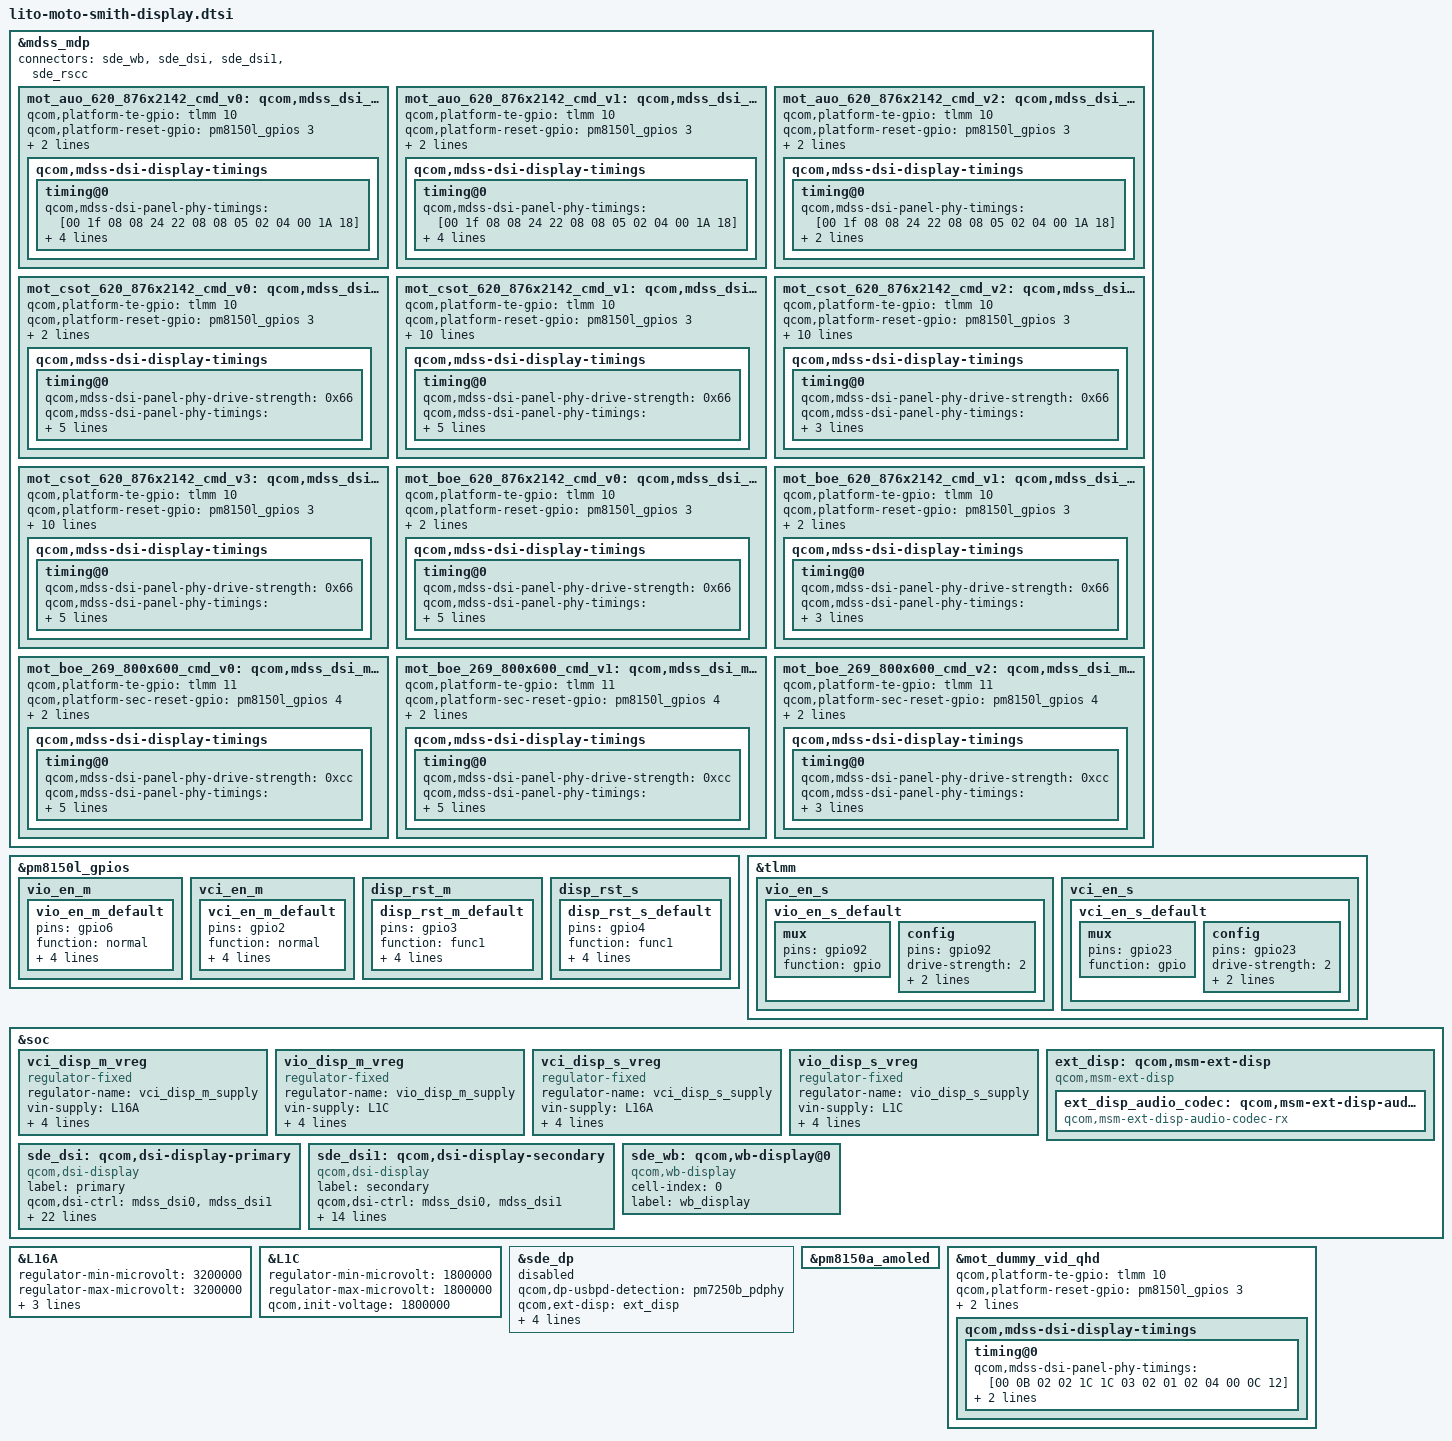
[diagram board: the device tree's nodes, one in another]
/* Copyright (c) 2019, The Linux Foundation. All rights reserved.
 *
 * This program is free software; you can redistribute it and/or modify
 * it under the terms of the GNU General Public License version 2 and
 * only version 2 as published by the Free Software Foundation.
 *
 * This program is distributed in the hope that it will be useful,
 * but WITHOUT ANY WARRANTY; without even the implied warranty of
 * MERCHANTABILITY or FITNESS FOR A PARTICULAR PURPOSE.  See the
 * GNU General Public License for more details.
 */
#include <dt-bindings/clock/mdss-7nm-pll-clk.h>
#include "dsi-panel-mot-dummy-qhd-video.dtsi"

&mdss_mdp {
	/* Primary Display: AUO */
	mot_auo_620_876x2142_cmd_v0: qcom,mdss_dsi_mot_auo_620_876x2142_cmd_v0 {
		#include "dsi-panel-mot-auo-620-876x2142-cmd-common.dtsi"
	};

	mot_auo_620_876x2142_cmd_v1: qcom,mdss_dsi_mot_auo_620_876x2142_cmd_v1 {
		#include "dsi-panel-mot-auo-620-876x2142-cmd-common.dtsi"
	};

	mot_auo_620_876x2142_cmd_v2: qcom,mdss_dsi_mot_auo_620_876x2142_cmd_v2 {
		#include "dsi-panel-mot-auo-620-876x2142-cmd-common.dtsi"
	};

        /* Primary Display:  CSOT */
        mot_csot_620_876x2142_cmd_v0: qcom,mdss_dsi_mot_csot_620_876x2142_cmd_v0 {
		#include "dsi-panel-mot-csot-620-876x2142-cmd-common.dtsi"
	};

	mot_csot_620_876x2142_cmd_v1: qcom,mdss_dsi_mot_csot_620_876x2142_cmd_v1 {
		#include "dsi-panel-mot-csot-620-876x2142-cmd-common.dtsi"
	};

	mot_csot_620_876x2142_cmd_v2: qcom,mdss_dsi_mot_csot_620_876x2142_cmd_v2 {
		#include "dsi-panel-mot-csot-620-876x2142-cmd-common.dtsi"
	};

	mot_csot_620_876x2142_cmd_v3: qcom,mdss_dsi_mot_csot_620_876x2142_cmd_v3 {
		#include "dsi-panel-mot-csot-620-876x2142-cmd-common.dtsi"
	};

	/* Primary Display:  BOE */
	mot_boe_620_876x2142_cmd_v0: qcom,mdss_dsi_mot_boe_620_876x2142_cmd_v0 {
		#include "dsi-panel-mot-boe-620-876x2142-cmd-common.dtsi"
	};

	/* Primary Display:  BOE */
	mot_boe_620_876x2142_cmd_v1: qcom,mdss_dsi_mot_boe_620_876x2142_cmd_v1 {
		#include "dsi-panel-mot-boe-620-876x2142-cmd-common.dtsi"
	};

	/* Secondary Display: BOE */
	mot_boe_269_800x600_cmd_v0: qcom,mdss_dsi_mot_boe_269_800x600_cmd_v0 {
		#include "dsi-panel-mot-boe-269-800x600-cmd-common.dtsi"
	};

	mot_boe_269_800x600_cmd_v1: qcom,mdss_dsi_mot_boe_269_800x600_cmd_v1 {
		#include "dsi-panel-mot-boe-269-800x600-cmd-common.dtsi"
	};

	mot_boe_269_800x600_cmd_v2: qcom,mdss_dsi_mot_boe_269_800x600_cmd_v2 {
		#include "dsi-panel-mot-boe-269-800x600-cmd-common.dtsi"
	};
};

&pm8150l_gpios {
        vio_en_m {
                vio_en_m_default: vio_en_m_default {
                        pins = "gpio6";
                        function = "normal";
                        qcom,drive-strength = <2>;
                        power-source = <0>;
                        bias-disable;
                        output-high;
                };
        };

	vci_en_m {
		vci_en_m_default: vci_en_m_default {
			pins = "gpio2";
			function = "normal";
			qcom,drive-strength = <2>;
			power-source = <0>;
			bias-disable;
			output-high;
		};
	};

        disp_rst_m {
                disp_rst_m_default: disp_rst_m_default {
                        pins = "gpio3";
                        function = "func1";
                        qcom,drive-strength = <2>;
                        power-source = <0>;
                        bias-disable;
                        output-low;
                };
	};

	disp_rst_s {
		disp_rst_s_default: disp_rst_s_default {
			pins = "gpio4";
			function = "func1";
			qcom,drive-strength = <2>;
			power-source = <0>;
			bias-disable;
			output-low;
		};
	};
};

&tlmm {
	vio_en_s {
		vio_en_s_default: vio_en_s_default {
			mux {
				pins = "gpio92";
				function = "gpio";
			};

			config {
				pins = "gpio92";
				drive-strength = <2>;   /* 2 mA */
				bias-no-pull;
				output-high;
			};
		};
	};

	vci_en_s {
		vci_en_s_default: vci_en_s_default {
			mux {
				pins = "gpio23";
				function = "gpio";
			};

			config {
				pins = "gpio23";
				drive-strength = <2>;   /* 2 mA */
				bias-no-pull;
				output-high;
			};
		};
	};
};

&soc {
	vci_disp_m_vreg: vci_disp_m_vreg {
		compatible = "regulator-fixed";
		regulator-name = "vci_disp_m_supply";
		vin-supply = <&L16A>;
		enable-active-high;
		regulator-boot-on;

		gpio = <&pm8150l_gpios 02 GPIO_ACTIVE_HIGH>;
		pinctrl-names = "default";
		pinctrl-0 = <&vci_en_m_default>;
	};

	vio_disp_m_vreg: vio_disp_m_vreg {
		compatible = "regulator-fixed";
		regulator-name = "vio_disp_m_supply";
		vin-supply = <&L1C>;
		enable-active-high;
		regulator-boot-on;

		gpio = <&pm8150l_gpios 6 GPIO_ACTIVE_HIGH>;
		pinctrl-names = "default";
		pinctrl-0 = <&vio_en_m_default>;
	};

	vci_disp_s_vreg: vci_disp_s_vreg {
		compatible = "regulator-fixed";
		regulator-name = "vci_disp_s_supply";
		vin-supply = <&L16A>;
		enable-active-high;
		regulator-boot-on;

		gpio = <&tlmm 23 GPIO_ACTIVE_HIGH>;
		pinctrl-names = "default";
		pinctrl-0 = <&vci_en_s_default>;
	};


	vio_disp_s_vreg: vio_disp_s_vreg {
		compatible = "regulator-fixed";
		regulator-name = "vio_disp_s_supply";
		vin-supply = <&L1C>;
		enable-active-high;
		regulator-boot-on;

		gpio = <&tlmm 92 GPIO_ACTIVE_HIGH>;
		pinctrl-names = "default";
		pinctrl-0 = <&vio_en_s_default>;
	};

	ext_disp: qcom,msm-ext-disp {
		compatible = "qcom,msm-ext-disp";

		ext_disp_audio_codec: qcom,msm-ext-disp-audio-codec-rx {
			compatible = "qcom,msm-ext-disp-audio-codec-rx";
		};
	};

	sde_dsi: qcom,dsi-display-primary {
		compatible = "qcom,dsi-display";
		label = "primary";

		qcom,dsi-ctrl = <&mdss_dsi0 &mdss_dsi1>;
		qcom,dsi-phy = <&mdss_dsi_phy0 &mdss_dsi_phy1>;

		clocks = <&mdss_dsi0_pll BYTECLK_MUX_0_CLK>,
			<&mdss_dsi0_pll PCLK_MUX_0_CLK>,
			<&mdss_dsi0_pll BYTECLK_SRC_0_CLK>,
			<&mdss_dsi0_pll PCLK_SRC_0_CLK>,
			<&mdss_dsi0_pll SHADOW_BYTECLK_SRC_0_CLK>,
			<&mdss_dsi0_pll SHADOW_PCLK_SRC_0_CLK>,
			<&mdss_dsi1_pll BYTECLK_MUX_1_CLK>,
			<&mdss_dsi1_pll PCLK_MUX_1_CLK>,
			<&mdss_dsi1_pll BYTECLK_SRC_1_CLK>,
			<&mdss_dsi1_pll PCLK_SRC_1_CLK>,
			<&mdss_dsi1_pll SHADOW_BYTECLK_SRC_1_CLK>,
			<&mdss_dsi1_pll SHADOW_PCLK_SRC_1_CLK>;
		clock-names = "mux_byte_clk0", "mux_pixel_clk0",
				"src_byte_clk0", "src_pixel_clk0",
				"shadow_byte_clk0", "shadow_pixel_clk0",
				"mux_byte_clk1", "mux_pixel_clk1",
				"src_byte_clk1", "src_pixel_clk1",
				"shadow_byte_clk1", "shadow_pixel_clk1";

		pinctrl-names = "panel_active", "panel_suspend";
		pinctrl-0 = <&sde_te_active &disp_rst_m_default>;
		pinctrl-1 = <&sde_te_suspend>;

		qcom,platform-te-gpio = <&tlmm 10 0>;
		qcom,panel-te-source = <0>;
		vci_disp-supply = <&vci_disp_m_vreg>;
		vio_disp-supply = <&vio_disp_m_vreg>;

		qcom,mdp = <&mdss_mdp>;
		qcom,dsi-default-panel = <&mot_boe_620_876x2142_cmd_v0>;
	};


	sde_dsi1: qcom,dsi-display-secondary {
		compatible = "qcom,dsi-display";
		label = "secondary";

		qcom,dsi-ctrl = <&mdss_dsi0 &mdss_dsi1>;
		qcom,dsi-phy = <&mdss_dsi_phy0 &mdss_dsi_phy1>;

		clocks = <&mdss_dsi0_pll BYTECLK_MUX_0_CLK>,
			<&mdss_dsi0_pll PCLK_MUX_0_CLK>,
			<&mdss_dsi1_pll BYTECLK_MUX_1_CLK>,
			<&mdss_dsi1_pll PCLK_MUX_1_CLK>;
		clock-names = "mux_byte_clk0", "mux_pixel_clk0",
				"mux_byte_clk1", "mux_pixel_clk1";

		pinctrl-names = "panel_active", "panel_suspend";
		pinctrl-0 = <&sde_te1_active &disp_rst_s_default>;
		pinctrl-1 = <&sde_te1_suspend>;

		qcom,platform-te-gpio = <&tlmm 11 0>;
		qcom,panel-te-source = <1>;
		vio_disp-supply = <&vio_disp_s_vreg>;
		vci_disp-supply = <&vci_disp_s_vreg>;

		qcom,mdp = <&mdss_mdp>;
                qcom,dsi-default-panel = <&mot_boe_269_800x600_cmd_v1>;
	};

	sde_wb: qcom,wb-display@0 {
		compatible = "qcom,wb-display";
		cell-index = <0>;
		label = "wb_display";
	};
};

&L16A {
	regulator-min-microvolt = <3200000>;
	regulator-max-microvolt = <3200000>;
	qcom,init-voltage = <3200000>;
	regulator-always-on;
	regulator-boot-on;
};


&L1C {
	regulator-min-microvolt = <1800000>;
	regulator-max-microvolt = <1800000>;
	qcom,init-voltage = <1800000>;
};


&sde_dp {
	status = "disabled";
	qcom,dp-usbpd-detection = <&pm7250b_pdphy>;
	qcom,ext-disp = <&ext_disp>;
	qcom,dp-aux-switch = <&fsa4480>;

	qcom,usbplug-cc-gpio = <&tlmm 114 0>;

	pinctrl-names = "mdss_dp_active", "mdss_dp_sleep";
	pinctrl-0 = <&sde_dp_usbplug_cc_active>;
	pinctrl-1 = <&sde_dp_usbplug_cc_suspend>;
};

&pm8150a_amoled {
	status = "ok";
};

&mdss_mdp {
	connectors = <&sde_wb &sde_dsi &sde_dsi1 &sde_rscc>;
};

&mot_auo_620_876x2142_cmd_v0 {
	qcom,platform-te-gpio = <&tlmm 10 0>;
	qcom,platform-reset-gpio = <&pm8150l_gpios 3 0>;

	qcom,dsi-select-clocks = "mux_byte_clk0", "mux_pixel_clk0";
	qcom,mdss-dsi-display-timings {
		timing@0{
			qcom,mdss-dsi-panel-phy-timings = [00 1f 08 08 24 22 08
							08 05 02 04 00 1A 18];
			qcom,display-topology = <1 0 1>;
			qcom,default-topology-index = <0>;
			qcom,mdss-dsi-on-command = [
				15 00 00 00 00 00 02 FE 40
				15 00 00 00 00 00 02 05 06
				15 00 00 00 00 00 02 06 0C
				15 00 00 00 00 00 02 08 06
				15 00 00 00 00 00 02 09 0C
				15 00 00 00 00 00 02 FE 60
				15 00 00 00 00 00 02 38 C4
				15 00 00 00 00 00 02 43 C4
				15 00 00 00 00 00 02 FE 70
				15 00 00 00 00 00 02 7D 35
				15 00 00 00 00 00 02 FE 00
				05 01 00 00 78 00 01 11
				15 00 00 00 00 00 02 35 00
				15 00 00 00 00 00 02 53 20 /* HBM off ,dimming=1frame*/
				15 00 00 00 00 00 02 51 00
				15 00 00 00 00 00 02 55 00      /* ACL OFF */
				05 01 00 00 00 00 01 29];       /* display on */
		};
	};
};

&mot_auo_620_876x2142_cmd_v1 {
	qcom,platform-te-gpio = <&tlmm 10 0>;
	qcom,platform-reset-gpio = <&pm8150l_gpios 3 0>;

	qcom,dsi-select-clocks = "mux_byte_clk0", "mux_pixel_clk0";
	qcom,mdss-dsi-display-timings {
		timing@0{
			qcom,mdss-dsi-panel-phy-timings = [00 1f 08 08 24 22 08
							08 05 02 04 00 1A 18];
			qcom,display-topology = <1 0 1>;
			qcom,default-topology-index = <0>;
			qcom,mdss-dsi-on-command = [
				15 00 00 00 00 00 02 FE 70 /* Switch to page 70 */
				15 00 00 00 00 00 02 CB 05
				15 00 00 00 00 00 02 7D 31 /* Use source mode */
				15 00 00 00 00 00 02 7E 4A /* Enable source mode linear light curve */
				15 00 00 00 00 00 02 49 00
				15 00 00 00 00 00 02 4A 2E
				15 00 00 00 00 00 02 4B 50
				15 00 00 00 00 00 02 4C 70
				15 00 00 00 00 00 02 4D 9C
				15 00 00 00 00 00 02 4E D0
				15 00 00 00 00 00 02 4F 21
				15 00 00 00 00 00 02 50 90
				15 00 00 00 00 00 02 51 24
				15 00 00 00 00 00 02 AD EA
				15 00 00 00 00 00 02 AE 80
				15 00 00 00 00 00 02 AF 00
				15 00 00 00 00 00 02 B0 50
				15 00 00 00 00 00 02 B1 3A
				15 00 00 00 00 00 02 FE 00 /* switch back to page 0 */
				05 01 00 00 78 00 01 11
				15 00 00 00 00 00 02 35 00
				15 00 00 00 00 00 02 53 20 /* HBM off ,dimming=1frame*/
				15 00 00 00 00 00 02 51 00
				15 00 00 00 00 00 02 55 00      /* ACL OFF */
				05 01 00 00 00 00 01 29];       /* display on */
			};
	};
};

&mot_auo_620_876x2142_cmd_v2 {
	qcom,platform-te-gpio = <&tlmm 10 0>;
	qcom,platform-reset-gpio = <&pm8150l_gpios 3 0>;

	qcom,dsi-select-clocks = "mux_byte_clk0", "mux_pixel_clk0";
	qcom,mdss-dsi-display-timings {
		timing@0{
			qcom,mdss-dsi-panel-phy-timings = [00 1f 08 08 24 22 08
							08 05 02 04 00 1A 18];
			qcom,display-topology = <1 0 1>;
			qcom,default-topology-index = <0>;
		};
	};
};

&mot_boe_620_876x2142_cmd_v0 {
	qcom,platform-te-gpio = <&tlmm 10 0>;
	qcom,platform-reset-gpio = <&pm8150l_gpios 3 0>;

	qcom,dsi-select-clocks = "mux_byte_clk0", "mux_pixel_clk0";
	qcom,mdss-dsi-display-timings {
		timing@0{
			qcom,mdss-dsi-panel-phy-drive-strength = <0x66>;
			qcom,mdss-dsi-panel-phy-timings = [00 1f 08 08 24 22 08
							08 08 02 04 00 1B 18];
			qcom,display-topology = <1 0 1>;
			qcom,default-topology-index = <0>;
			qcom,mdss-dsi-on-command = [
				15 00 00 00 00 00 02 FE D0
				15 00 00 00 00 00 02 99 00
				15 00 00 00 00 00 02 FE 40
				15 00 00 00 00 00 02 74 2E
				15 00 00 00 00 00 02 80 19
				15 00 00 00 00 00 02 FE E0
				15 00 00 00 00 00 02 9A D7
				15 00 00 00 00 00 02 91 19
				15 00 00 00 00 00 02 92 14
				15 00 00 00 00 00 02 FE 40
				15 00 00 00 00 00 02 9A 00
				15 00 00 00 00 00 02 FE 00
				15 00 00 00 00 00 02 35 00
				15 00 00 00 00 00 02 5E 01
				15 00 00 00 00 00 02 C2 08
				15 00 00 00 00 00 02 53 20 /*HBM off ,dimming=1frame*/
				15 00 00 00 00 00 02 55 00      /*ACL OFF */
				15 00 00 00 00 00 02 51 00
				05 01 00 00 78 00 01 11
				05 01 00 00 00 00 01 29];       /* display on */
		};
	};
};

&mot_boe_620_876x2142_cmd_v1 {
	qcom,platform-te-gpio = <&tlmm 10 0>;
	qcom,platform-reset-gpio = <&pm8150l_gpios 3 0>;

	qcom,dsi-select-clocks = "mux_byte_clk0", "mux_pixel_clk0";
	qcom,mdss-dsi-display-timings {
		timing@0{
			qcom,mdss-dsi-panel-phy-drive-strength = <0x66>;
			qcom,mdss-dsi-panel-phy-timings = [00 1f 08 08 24 22 08
							08 08 02 04 00 1B 18];
			qcom,display-topology = <1 0 1>;
			qcom,default-topology-index = <0>;
		};
	};
};

&mot_csot_620_876x2142_cmd_v0 {
	qcom,platform-te-gpio = <&tlmm 10 0>;
	qcom,platform-reset-gpio = <&pm8150l_gpios 3 0>;
	qcom,dsi-select-clocks = "mux_byte_clk0", "mux_pixel_clk0";

	qcom,mdss-dsi-display-timings {
		timing@0{
			qcom,mdss-dsi-panel-phy-drive-strength = <0x66>;
			qcom,mdss-dsi-panel-phy-timings = [00 1f 08 08 24 22 08
							08 08 02 04 00 1B 18];
			qcom,display-topology = <1 0 1>;
			qcom,default-topology-index = <0>;

			qcom,mdss-dsi-on-command = [
				15 00 00 00 00 00 02 FE 40 /*switch CMD2*/
				15 00 00 00 00 00 02 9A 00 /*corner R function off, 0x00 for off, 0x01 for on*/
				15 00 00 00 00 00 02 FE 00 /*return to CMD0*/
				05 01 00 00 78 00 01 11
				15 00 00 00 00 00 02 35 00
				15 00 00 00 00 00 02 53 20 /* HBM off ,dimming=1frame*/
				15 00 00 00 00 00 02 51 00
				15 00 00 00 00 00 02 55 00      /* ACL OFF */
				05 01 00 00 00 00 01 29];	/* display on */
		};
	};
};

&mot_csot_620_876x2142_cmd_v1 {
	qcom,platform-te-gpio = <&tlmm 10 0>;
	qcom,platform-reset-gpio = <&pm8150l_gpios 3 0>;

	qcom,bklt-dcs-2bytes-enabled;
	qcom,mdss-dsi-bl-min-level = <3>;
	qcom,mdss-dsi-bl-max-level = <2047>;

	qcom,mdss-dsi-hbm-on-command = [39 01 00 00 00 00 03 51 0F FF];
	qcom,mdss-dsi-hbm-off-command = [39 01 00 00 00 00 03 51 07 FF];

	qcom,mdss-dsi-panel-hbm-is-51cmd;

	qcom,dsi-select-clocks = "mux_byte_clk0", "mux_pixel_clk0";
	qcom,mdss-dsi-display-timings {
	        timing@0{
			qcom,mdss-dsi-panel-phy-drive-strength = <0x66>;
			qcom,mdss-dsi-panel-phy-timings = [00 1f 08 08 24 22 08
							08 08 02 04 00 1B 18];
			qcom,display-topology = <1 0 1>;
			qcom,default-topology-index = <0>;

			qcom,mdss-dsi-on-command = [
				15 00 00 00 00 00 02 FE 40 /*switch CMD2*/
				15 00 00 00 00 00 02 9A 00 /* corner R function off, 0x00 for off, 0x01 for on*/
				15 00 00 00 00 00 02 6F 02 /*swire update by vsync*/
				15 00 00 00 00 00 02 FE 00
				15 00 00 00 00 00 02 5E 01 /* swire control Enable */
				15 00 00 00 00 00 02 FE E0 /* */
				15 00 00 00 00 00 02 C3 00 /* Enable Avg Y */
				15 00 00 00 00 00 02 8B 12 /* ops dimming off*/
				15 00 00 00 00 00 02 8E 21 /* Step width*/
				15 00 00 00 00 00 02 90 14 /* First pulse width*/
				15 00 00 00 00 00 02 FE 70 /* */
				15 00 00 00 00 00 02 11 C0 /* Ops_ref_bc */
				15 00 00 00 00 00 02 17 00 /* opsen_3mode */
				/* Lookup table setting swire pulse */
				15 00 00 00 00 00 02 FE E0 /* */
				15 00 00 00 00 00 02 91 19 /* lut1 = -3v */
				15 00 00 00 00 00 02 92 19 /* lut2 = -3v */
				15 00 00 00 00 00 02 93 19 /* lut3 = -3v */
				15 00 00 00 00 00 02 94 19 /* lut4 = -3v */
				15 00 00 00 00 00 02 95 0F /* lut5 = -3v */
				15 00 00 00 00 00 02 96 0F /* lut6 = -3v */
				15 00 00 00 00 00 02 97 0F /* lut7 = -3v */
				15 00 00 00 00 00 02 98 0F /* lut8 = -3v */
				15 00 00 00 00 00 02 99 0F /* lut9 = -3v */
				/* Lookup table setting 51 ratio */
				15 00 00 00 00 00 02 9A 7F /* lut1 = 000~7FF */
				15 00 00 00 00 00 02 9B 7F /* lut2 = 000~7FF */
				15 00 00 00 00 00 02 9C 7F /* lut3 = 000~7FF */
				15 00 00 00 00 00 02 9D 7F /* lut4 = 800~7FF */
				15 00 00 00 00 00 02 9E FF /* lut5 = 800~7FF */
				15 00 00 00 00 00 02 9F FF /* lut6 = 800~7FF */
				15 00 00 00 00 00 02 A0 FF /* lut7 = 800~7FF */
				15 00 00 00 00 00 02 A2 FF /* lut8 = 800~7FF */
				15 00 00 00 00 00 02 FE 00
				15 00 00 00 00 00 02 C2 08
				05 01 00 00 78 00 01 11
				15 00 00 00 00 00 02 35 00
				15 00 00 00 00 00 02 53 20 /* HBM off ,dimming=1frame*/
				39 00 00 00 00 00 03 51 00 00
				15 00 00 00 00 00 02 55 00      /* ACL OFF */
				05 01 00 00 00 00 01 29];       /* display on */
		};
	};
};

&mot_csot_620_876x2142_cmd_v2 {
	qcom,platform-te-gpio = <&tlmm 10 0>;
	qcom,platform-reset-gpio = <&pm8150l_gpios 3 0>;

	qcom,bklt-dcs-2bytes-enabled;
	qcom,mdss-dsi-bl-min-level = <3>;
	qcom,mdss-dsi-bl-max-level = <2047>;

	qcom,mdss-dsi-hbm-on-command = [39 01 00 00 00 00 03 51 0F FF];
	qcom,mdss-dsi-hbm-off-command = [39 01 00 00 00 00 03 51 07 FF];

	qcom,mdss-dsi-panel-hbm-is-51cmd;

	qcom,dsi-select-clocks = "mux_byte_clk0", "mux_pixel_clk0";
	qcom,mdss-dsi-display-timings {
		timing@0{
			qcom,mdss-dsi-panel-phy-drive-strength = <0x66>;
			qcom,mdss-dsi-panel-phy-timings = [00 1f 08 08 24 22 08
							08 08 02 04 00 1B 18];
			qcom,display-topology = <1 0 1>;
			qcom,default-topology-index = <0>;
		};
	};
};

&mot_csot_620_876x2142_cmd_v3 {
	qcom,platform-te-gpio = <&tlmm 10 0>;
	qcom,platform-reset-gpio = <&pm8150l_gpios 3 0>;

	qcom,bklt-dcs-2bytes-enabled;
	qcom,mdss-dsi-bl-min-level = <3>;
	qcom,mdss-dsi-bl-max-level = <2047>;

	qcom,mdss-dsi-hbm-on-command = [39 01 00 00 00 00 03 51 0F FF];
	qcom,mdss-dsi-hbm-off-command = [39 01 00 00 00 00 03 51 07 FF];

	qcom,mdss-dsi-panel-hbm-is-51cmd;

	qcom,dsi-select-clocks = "mux_byte_clk0", "mux_pixel_clk0";
	qcom,mdss-dsi-display-timings {
		timing@0{
			qcom,mdss-dsi-panel-phy-drive-strength = <0x66>;
			qcom,mdss-dsi-panel-phy-timings = [00 1f 08 08 24 22 08
							08 08 02 04 00 1B 18];
			qcom,display-topology = <1 0 1>;
			qcom,default-topology-index = <0>;
			qcom,mdss-dsi-on-command = [
				15 00 00 00 00 00 02 FE 40 /*switch CMD2*/
				15 00 00 00 00 00 02 9A 00 /* corner R function off, 0x00 for off, 0x01 for on*/
				15 00 00 00 00 00 02 FE 50
				15 00 00 00 00 00 02 E2 80
				15 00 00 00 00 00 02 E3 80
				15 00 00 00 00 00 02 E4 01
				15 00 00 00 00 00 02 FE 52
				15 00 00 00 00 00 02 E2 80
				15 00 00 00 00 00 02 E3 80
				15 00 00 00 00 00 02 E4 01
				15 00 00 00 00 00 02 FE 74
				15 00 00 00 00 00 02 00 00
				15 00 00 00 00 00 02 01 00
				15 00 00 00 00 00 02 02 11
				15 00 00 00 00 00 02 03 07
				15 00 00 00 00 00 02 04 0F
				15 00 00 00 00 00 02 05 00
				15 00 00 00 00 00 02 06 00
				15 00 00 00 00 00 02 07 19
				15 00 00 00 00 00 02 08 61
				15 00 00 00 00 00 02 09 24
				15 00 00 00 00 00 02 0A E7
				15 00 00 00 00 00 02 0B FF
				15 00 00 00 00 00 02 0C 00
				15 00 00 00 00 00 02 0D FF
				15 00 00 00 00 00 02 0E 7C
				15 00 00 00 00 00 02 61 7C
				15 00 00 00 00 00 02 0F 00
				15 00 00 00 00 00 02 10 04
				15 00 00 00 00 00 02 11 00
				15 00 00 00 00 00 02 12 00
				15 00 00 00 00 00 02 13 04
				15 00 00 00 00 00 02 14 05
				15 00 00 00 00 00 02 15 06
				15 00 00 00 00 00 02 16 02
				15 00 00 00 00 00 02 17 01
				15 00 00 00 00 00 02 18 00
				15 00 00 00 00 00 02 19 03
				15 00 00 00 00 00 02 22 04
				15 00 00 00 00 00 02 43 3C
				15 00 00 00 00 00 02 44 00
				15 00 00 00 00 00 02 45 F0
				15 00 00 00 00 00 02 46 0F
				15 00 00 00 00 00 02 47 93
				15 00 00 00 00 00 02 48 FF
				15 00 00 00 00 00 02 49 FF
				15 00 00 00 00 00 02 4A CC
				15 00 00 00 00 00 02 4B FF
				15 00 00 00 00 00 02 4C FF
				15 00 00 00 00 00 02 4D CC
				15 00 00 00 00 00 02 4E 33
				15 00 00 00 00 00 02 4F 99
				15 00 00 00 00 00 02 50 FF
				15 00 00 00 00 00 02 51 FF
				15 00 00 00 00 00 02 52 FF
				15 00 00 00 00 00 02 53 FF
				15 00 00 00 00 00 02 FE 00
				05 01 00 00 78 00 01 11
				15 00 00 00 00 00 02 35 00
				39 00 00 00 00 00 03 51 00 FF
				15 00 00 00 00 00 02 55 00      /* ACL OFF */
				05 01 00 00 00 00 01 29];       /* display on */
		};
	};
};

&mot_boe_269_800x600_cmd_v0 {
	qcom,platform-te-gpio = <&tlmm 11 0>;
	qcom,platform-sec-reset-gpio = <&pm8150l_gpios 4 0>;

	qcom,dsi-select-sec-clocks = "mux_byte_clk1", "mux_pixel_clk1";
	qcom,mdss-dsi-display-timings {
		timing@0{
			qcom,mdss-dsi-panel-phy-drive-strength = <0xcc>;
			qcom,mdss-dsi-panel-phy-timings = [00 10 03 03 1E 1E 04
							04 03 02 04 00 10 13];
			qcom,display-topology = <1 0 1>;
			qcom,default-topology-index = <0>;
			qcom,mdss-dsi-on-command = [
				15 00 00 00 00 00 02 FE 72
				15 00 00 00 00 00 02 10 85
				15 00 00 00 00 00 02 FE 40 /* Switch to CMD2 */
				15 00 00 00 00 00 02 2F 80 /* fixed charged pump of power */
				15 00 00 00 00 00 02 31 80
				15 00 00 00 00 00 02 33 80
				15 00 00 00 00 00 02 35 80
				15 00 00 00 00 00 02 FE 00 /* Switch back CMD0 */
				05 01 00 00 78 00 01 11
				15 00 00 00 00 00 02 35 00
				15 00 00 00 00 00 02 53 20 /* HBM off ,dimming=1frame*/
				15 00 00 00 00 00 02 51 00
				15 00 00 00 00 00 02 55 00 /* ACL OFF */
				05 01 00 00 00 00 01 29];       /* display on */
		};
	};
};

&mot_boe_269_800x600_cmd_v1 {
	qcom,platform-te-gpio = <&tlmm 11 0>;
	qcom,platform-sec-reset-gpio = <&pm8150l_gpios 4 0>;

	qcom,dsi-select-sec-clocks = "mux_byte_clk1", "mux_pixel_clk1";
	qcom,mdss-dsi-display-timings {
		timing@0{
			qcom,mdss-dsi-panel-phy-drive-strength = <0xcc>;
			qcom,mdss-dsi-panel-phy-timings = [00 10 03 03 1E 1E 04
							04 03 02 04 00 10 13];
			qcom,display-topology = <1 0 1>;
			qcom,default-topology-index = <0>;
			qcom,mdss-dsi-on-command = [
				15 00 00 00 00 00 02 FE 40 /* Switch to CMD2 */
				15 00 00 00 00 00 02 2F 80 /* Fixed charged pump of power */
				15 00 00 00 00 00 02 31 80
				15 00 00 00 00 00 02 33 80
				15 00 00 00 00 00 02 35 80
				15 00 00 00 00 00 02 24 50
				15 00 00 00 00 00 02 47 13
				15 00 00 00 00 00 02 FE 50
				15 00 00 00 00 00 02 C0 20
				15 00 00 00 00 00 02 FE 60 /* Switch to CMD2 */
				15 00 00 00 00 00 02 95 CE /* EM pull high */
				15 00 00 00 00 00 02 FE 00 /* Switch back CMD0 */
				05 01 00 00 78 00 01 11
				15 00 00 00 00 00 02 35 00
				15 00 00 00 00 00 02 53 20 /* HBM off ,dimming=1frame*/
				15 00 00 00 00 00 02 51 00
				15 00 00 00 00 00 02 55 00 /* ACL OFF */
				05 01 00 00 00 00 01 29];       /* display on */
		};
	};
};

&mot_boe_269_800x600_cmd_v2 {
	qcom,platform-te-gpio = <&tlmm 11 0>;
	qcom,platform-sec-reset-gpio = <&pm8150l_gpios 4 0>;

	qcom,dsi-select-sec-clocks = "mux_byte_clk1", "mux_pixel_clk1";
	qcom,mdss-dsi-display-timings {
		timing@0{
			qcom,mdss-dsi-panel-phy-drive-strength = <0xcc>;
			qcom,mdss-dsi-panel-phy-timings = [00 10 03 03 1E 1E 04
							04 03 02 04 00 10 13];

			qcom,display-topology = <1 0 1>;
			qcom,default-topology-index = <0>;
		};
	};
};

&mot_dummy_vid_qhd {
	qcom,platform-te-gpio = <&tlmm 10 0>;
	qcom,platform-reset-gpio = <&pm8150l_gpios 3 0>;

	qcom,dsi-select-clocks = "mux_byte_clk0", "mux_pixel_clk0";
	qcom,mdss-dsi-display-timings {
		timing@0 {
			qcom,mdss-dsi-panel-phy-timings = [00 0B 02 02 1C 1C 03
							02 01 02 04 00 0C 12];
			qcom,display-topology = <1 0 1>;
			qcom,default-topology-index = <0>;
		};
	};
};
